# RCSS_SCI register map
Vendor: Texas Instruments
Peripheral module from a debugger description file (folder am273).
Registers are 32-bit, access per field, no defined reset value unless marked. A register's access mark holds for its fields unless they carry their own. Offsets are as the file gives them; lines under a group give offsets from that group; [hi:lo] are bit positions; {n}, {i} and the like mark numbered series; 'fields as' and 'values as' point back to an identical list; <NAME> marks a mode.

## RCSS_SCI
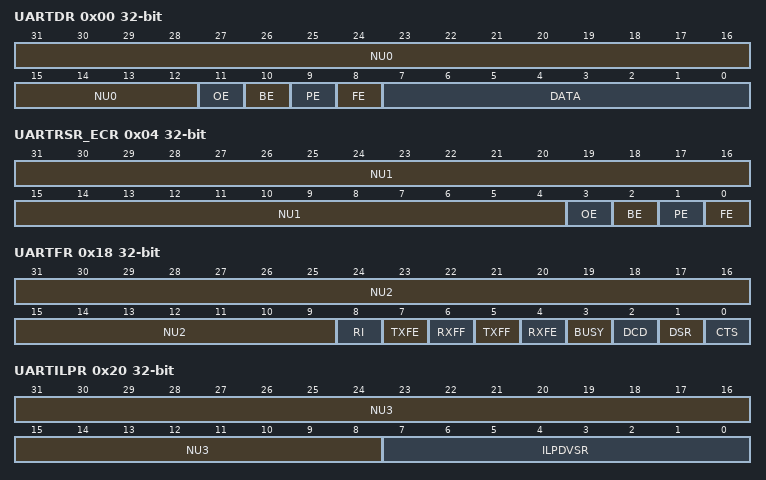
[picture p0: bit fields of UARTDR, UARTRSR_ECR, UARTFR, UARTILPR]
0x00 UARTDR — Data Register, UARTDR
  [31:12] NU0 ro — Reserved.
  [11] OE rw — Overrun error. This bit is set to 1 if data is received and the receive FIFO is already full. This is cleared to 0 once there is an empty space in the FIFO and a new character can be written to it.
  [10] BE rw — Break error. This bit is set to 1 if a break condition was detected, indicating that the received data input was held LOW for longer than a full-word transmission time (defined as start, data, parity and stop bits). In FIFO mode, this error is associated with the character at the top of the FIFO. When a break occurs, only one 0 character is loaded into the FIFO. The next character is only enabled after the receive data input goes to a 1 (marking state), and the next valid start bit is received
  [9] PE rw — Parity error. When set to 1, it indicates that the parity of the received data character does not match the parity that the EPS and SPS bits in the Line Control Register, UARTLCR. In FIFO mode, this error is associated with the character at the top of the FIFO.
  [8] FE rw — Framing error. When set to 1, it indicates that the received character did not have a valid stop bit (a valid stop bit is 1). In FIFO mode, this error is associated with the character at the top of the FIFO
  [7:0] DATA rw — Receive data character & Transmit data character
0x04 UARTRSR_ECR — Receive Status Register/Error Clear Register,
  [31:4] NU1 ro — Reserved, unpredictable when read
  [3] OE rw — Overrun error. This bit is set to 1 if data is received and the FIFO is already full. This bit is cleared to 0 by a write to UARTECR. The FIFO contents remain valid because no more data is written when the FIFO is full, only the contents of the shift register are overwritten. The CPU must now read the data, to empty the FIFO.
  [2] BE rw — Break error. This bit is set to 1 if a break condition was detected, indicating that the received data input was held LOW for longer than a full-word transmission time (defined as start, data, parity, and stop bits). This bit is cleared to 0 after a write to UARTECR. In FIFO mode, this error is associated with the character at the top of the FIFO. When a break occurs, only one 0 character is loaded into the FIFO. The next character is only enabled after the receive data input goes to a 1 (marking state) and the next valid start bit is received.
  [1] PE rw — Parity error. When set to 1, it indicates that the parity of the received data character does not match the parity that the EPS and SPS bits in the Line Control Register, UARTLCR_H. This bit is cleared to 0 by a write to UARTECR. In FIFO mode, this error is associated with the character at the top of the FIFO.
  [0] FE rw — Framing error. When set to 1, it indicates that the received character did not have a valid stop bit (a valid stop bit is 1). This bit is cleared to 0 by a write to UARTECR. In FIFO mode, this error is associated with the character at the top of the FIFO.
0x18 UARTFR ro — Flag Register, UARTFR
  [31:9] NU2 — Reserved, do not modify, read as zero.
  [8] RI — Ring indicator. This bit is the complement of the UART ring indicator, nUARTRI, modem status input. That is, the bit is 1 when nUARTRI is LOW.
  [7] TXFE — Transmit FIFO empty. The meaning of this bit depends on the state of the FEN bit in the Line Control Register, UARTLCR_H. If the FIFO is disabled, this bit is set when the transmit holding register is empty.If the FIFO is enabled, the TXFE bit is set when the transmit FIFO is empty. This bit does not indicate if there is data in the transmit shift register.
  [6] RXFF — Receive FIFO full. The meaning of this bit depends on the state of the FEN bit in the UARTLCR_H Register. If the FIFO is disabled, this bit is set when the receive holding register is full. If the FIFO is enabled, the RXFF bit is set when the receive FIFO is full.
  [5] TXFF — Transmit FIFO full. The meaning of this bit depends on the state of the FEN bit in the UARTLCR_H Register. If the FIFO is disabled, this bit is set when the transmit holding register is full. If the FIFO is enabled, the TXFF bit is set when the transmit FIFO is full.
  [4] RXFE — Receive FIFO empty. The meaning of this bit depends on the state of the FEN bit in the UARTLCR_H Register. If the FIFO is disabled, this bit is set when the receive holding register is empty. If the FIFO is enabled, the RXFE bit is set when the receive FIFO is empty.
  [3] BUSY — UART busy. If this bit is set to 1, the UART is busy transmitting data. This bit remains set until the complete byte, including all the stop bits, has been sent from the shift register. This bit is set as soon as the transmit FIFO becomes non-empty, regardless of whether the UART is enabled or not.
  [2] DCD — Data carrier detect. This bit is the complement of the UART data carrier detect, nUARTDCD, modem status input. That is, the bit is 1 when nUARTDCD is LOW.
  [1] DSR — Data set ready. This bit is the complement of the UART data set ready, nUARTDSR, modem status input. That is, the bit is 1 when nUARTDSR is LOW.
  [0] CTS — Clear to send. This bit is the complement of the
0x20 UARTILPR — IrDA Low-Power Counter Register, UARTILPR
  [31:8] NU3 ro — Reserved.
  [7:0] ILPDVSR rw — 8-bit low-power divisor value. NOTE Zero is an illegal value. Programming a zero value results in no IrLPBaud16 pulses being generated
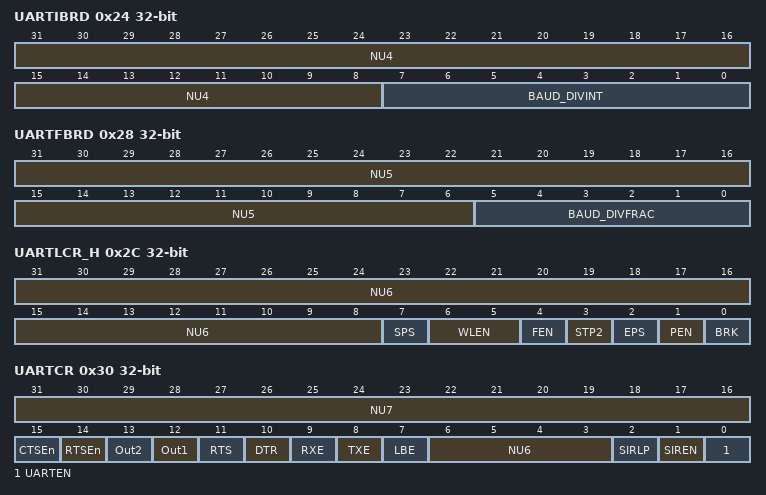
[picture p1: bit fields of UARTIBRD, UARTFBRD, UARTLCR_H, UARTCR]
0x24 UARTIBRD — Integer Baud Rate Register, UARTIBRD
  [31:8] NU4 ro — Reserved.
  [7:0] BAUD_DIVINT rw — The fractional baud rate divisor.
0x28 UARTFBRD — Fractional Baud Rate Register, UARTFBRD
  [31:6] NU5 ro — Reserved.
  [5:0] BAUD_DIVFRAC rw — The fractional baud rate divisor. Baud rate divisor BAUDDIV = (FUARTCLK/(16�Baud rate)) where FUARTCLK is the UART reference clock frequency. If the required baud rate is 230400 and UARTCLK = 4MHz then: Baud Rate Divisor = (4�106)/(16�230400) = 1.085 This means BRDI = 1 and BRDF = 0.085. Therefore, fractional part, m = integer((0.085�64)+0.5) = 5 Generated baud rate divider = 1+5/64 = 1.078 Generated baud rate = (4�106)/(16�1.078) = 231911 Error = (231911-230400)/230400 � 100 = 0.656% The maximum error using a 6-bit UARTFBRD Register = 1/64�100 = 1.56%. This occurs when m = 1, and the error is cumulative over 64 clock ticks.
0x2C UARTLCR_H — Line Control Register, UARTLCR_H
  [31:8] NU6 ro — Reserved, do not modify, read as zero.
  [7] SPS rw — Stick parity select. 0 = stick parity is disabled 1 = if the EPS bit is 0 then the parity bit is transmitted and checked as a 1 & if the EPS bit is 1 then the parity bit is transmitted and checked as a 0. This bit has no effect when the PEN bit disables parity checking and generation.
  [6:5] WLEN rw — Word length. These bits indicate the number of data bits transmitted or received in a frame as follows b11 = 8 bits b10 = 7 bits b01 = 6 bits b00 = 5 bits.
  [4] FEN rw — Enable FIFOs: 0 = FIFOs are disabled (character mode) that is, the FIFOs become 1-byte-deep holding registers 1 = transmit and receive FIFO buffers are enabled (FIFO mode).
  [3] STP2 rw — Two stop bits select. If this bit is set to 1, two stop bits are transmitted at the end of the frame. The receive logic does not check for two stop bits being received.
  [2] EPS rw — Even parity select. Controls the type of parity the UART uses during transmission and reception: 0 = odd parity. The UART generates or checks for an odd number of 1s in the data and parity bits. 1 = even parity. The UART generates or checks for an even number of 1s in the data and parity bits. This bit has no effect when the PEN bit disables parity checking and generation.
  [1] PEN rw — Parity enable: 0 = parity is disabled and no parity bit added to the data frame 1 = parity checking and generation is enabled.
  [0] BRK rw — Send break. If this bit is set to 1, a low-level is continually output on the UARTTXD output, after completing transmission of the current character. For the proper execution of the break command, the software must set this bit for at least two complete frames. For normal use, this bit must be cleared to 0.
0x30 UARTCR — Control Register, UARTCR
  [31:16] NU7 ro — Reserved, do not modify, read as zero.
  [15] CTSEn rw — CTS hardware flow control enable. If this bit is set to 1, CTS hardware flow control is enabled. Data is only transmitted when the nUARTCTS signal is asserted.
  [14] RTSEn rw — RTS hardware flow control enable. If this bit is set to 1, RTS hardware flow control is enabled. Data is only requested when there is space in the receive FIFO for it to be received.
  [13] Out2 rw — This bit is the complement of the UART Out2 (nUARTOut2) modem status output. That is, when the bit is programmed to a 1, the output is 0. For DTE this can be used as Ring Indicator (RI).
  [12] Out1 rw — This bit is the complement of the UART Out1 (nUARTOut1) modem status output. That is, when the bit is programmed to a 1 the output is 0. For DTE this can be used as Data Carrier Detect (DCD).
  [11] RTS rw — Request to send. This bit is the complement of the UART request to send, nUARTRTS, modem status output. That is, when the bit is programmed to a 1 then nUARTRTS is LOW.
  [10] DTR rw — Data transmit ready. This bit is the complement of the UART data transmit ready, nUARTDTR, modem status output. That is, when the bit is programmed to a 1 then nUARTDTR is LOW.
  [9] RXE rw — Receive enable. If this bit is set to 1, the receive section of the UART is enabled. Data reception occurs for either UART signals or SIR signals depending on the setting of the SIREN bit. When the UART is disabled in the middle of reception, it completes the current character before stopping.
  [8] TXE rw — Transmit enable. If this bit is set to 1, the transmit section of the UART is enabled. Data transmission occurs for either UART signals, or SIR signals depending on the setting of the SIREN bit. When the UART is disabled in the middle of transmission, it completes the current character before stopping.
  [7] LBE rw — Loopback enable. If this bit is set to 1 and the SIREN bit is set to 1 and the SIRTEST bit in the Test Control Register, UARTTCR on page 4-5 is set to 1, then the nSIROUT path is inverted, and fed through to the SIRIN path. The SIRTEST bit in the test register must be set to 1 to override the normal half-duplex SIR operation. This must be the requirement for accessing the test registers during normal operation, and SIRTEST must be cleared to 0 when loopback testing is finished. This feature reduces the amount of external coupling required during system test. If this bit is set to 1, and the SIRTEST bit is set to 0, the UARTTXD path is fed through to the UARTRXD path. In either SIR mode or UART mode, when this bit is set, the modem outputs are also fed through to the modem inputs. This bit is cleared to 0 on reset, to disable loopback.
  [6:3] NU6 ro — Reserved, do not modify, read as zero.
  [2] SIRLP rw — SIR low-power IrDA mode. This bit selects the IrDA encoding mode. If this bit is cleared to 0, low-level bits are transmitted as an active high pulse with a width of 3/16th of the bit period. If this bit is set to 1, low-level bits are transmitted with a pulse width that is 3 times the period of the IrLPBaud16 input signal, regardless of the selected bit rate. Setting this bit uses less power, but might reduce transmission distances.
  [1] SIREN rw — SIR enable: 0 = IrDA SIR ENDEC is disabled. nSIROUT remains LOW (no light pulse generated), and signal transitions on SIRIN have no effect. 1 = IrDA SIR ENDEC is enabled. Data is transmitted and received on nSIROUT and SIRIN. UARTTXD remains HIGH, in the marking state. Signal transitions on UARTRXD or modem status inputs have no effect. This bit has no effect if the UARTEN bit disables the UART.
  [0] UARTEN rw — UART enable: 0 = UART is disabled. If the UART is disabled in the middle of transmission or reception, it completes the current character before stopping. 1 = the UART is enabled. Data transmission and reception occurs for either UART signals or SIR signals depending on the setting of the SIREN bit.
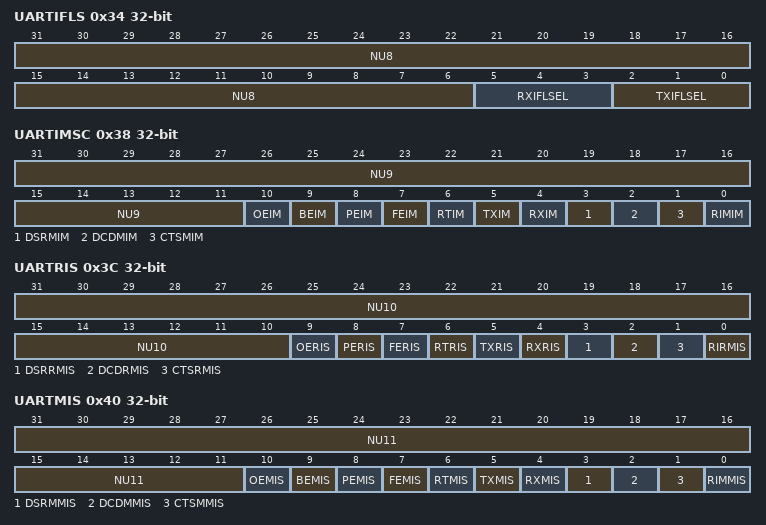
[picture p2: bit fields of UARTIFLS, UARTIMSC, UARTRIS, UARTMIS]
0x34 UARTIFLS — Interrupt FIFO Level Select Register, UARTIFLS
  [31:6] NU8 ro — Reserved, do not modify, read as zero.
  [5:3] RXIFLSEL rw — Receive interrupt FIFO level select. The trigger points for the receive interrupt are as follows: b000 = Receive FIFO becomes ≥ 1/8 full b001 = Receive FIFO becomes ≥ 1/4 full b010 = Receive FIFO becomes ≥ 1/2 full b011 = Receive FIFO becomes ≥ 3/4 full b100 = Receive FIFO becomes ≥ 7/8 full b101-b111 = reserved.
  [2:0] TXIFLSEL rw — Transmit interrupt FIFO level select. The trigger points for the transmit interrupt are as follows: b000 = Transmit FIFO becomes ≤ 1/8 full b001 = Transmit FIFO becomes ≤ 1/4 full b010 = Transmit FIFO becomes ≤ 1/2 full b011 = Transmit FIFO becomes ≤ 3/4 full b100 = Transmit FIFO becomes ≤ 7/8 full b101-b111 = reserved.
0x38 UARTIMSC — Interrupt Mask Set/Clear Register, UARTIMSC
  [31:11] NU9 ro — Reserved, read as zero, do not modify.
  [10] OEIM rw — Overrun error interrupt mask. A read returns the current mask for the UARTOEINTR interrupt.On a write of 1, the mask of the UARTOEINTR interrupt is set. A write of 0 clears the mask.
  [9] BEIM rw — Break error interrupt mask. A read returns the current mask for the UARTBEINTR interrupt. On a write of 1, the mask of the UARTBEINTR interrupt is set. A write of 0 clears the mask.
  [8] PEIM rw — Parity error interrupt mask. A read returns the current mask for the UARTPEINTR interrupt.On a write of 1, the mask of the UARTPEINTR interrupt is set. A write of 0 clears the mask.
  [7] FEIM rw — Framing error interrupt mask. A read returns the current mask for the UARTFEINTR interrupt.On a write of 1, the mask of the UARTFEINTR interrupt is set. A write of 0 clears the mask.
  [6] RTIM rw — Receive timeout interrupt mask. A read returns the current mask for the UARTRTINTR interrupt.On a write of 1, the mask of the UARTRTINTR interrupt is set. A write of 0 clears the mask.
  [5] TXIM rw — Transmit interrupt mask. A read returns the current mask for the UARTTXINTR interrupt.On a write of 1, the mask of the UARTTXINTR interrupt is set. A write of 0 clears the mask.
  [4] RXIM rw — Receive interrupt mask. A read returns the current mask for the UARTRXINTR interrupt.On a write of 1, the mask of the UARTRXINTR interrupt is set. A write of 0 clears the mask.
  [3] DSRMIM rw — nUARTDSR modem interrupt mask. A read returns the current mask for the UARTDSRINTR interrupt.On a write of 1, the mask of the UARTDSRINTR interrupt is set. A write of 0 clears the mask.
  [2] DCDMIM rw — nUARTDCD modem interrupt mask. A read returns the current mask for the UARTDCDINTR interrupt.On a write of 1, the mask of the UARTDCDINTR interrupt is set. A write of 0 clears the mask.
  [1] CTSMIM rw — nUARTCTS modem interrupt mask. A read returns the current mask for the UARTCTSINTR interrupt. On a write of 1, the mask of the UARTCTSINTR interrupt is set. A write of 0 clears the mask.
  [0] RIMIM rw — nUARTRI modem interrupt mask. A read returns the current mask for the UARTRIINTR interrupt.On a write of 1, the mask of the UARTRIINTR interrupt is set. A write of 0 clears the mask.
0x3C UARTRIS ro — Raw Interrupt Status Register, UARTRIS
  [31:10] NU10 — Reserved, read as zero, do not modify.
  [9] OERIS — Overrun error interrupt status. Returns the raw interrupt state of the UARTOEINTR interrupt. BERIS Break error interrupt status. Returns the raw interrupt state of the UARTBEINTR interrupt.
  [8] PERIS — Parity error interrupt status. Returns the raw interrupt state of the UARTPEINTR interrupt.
  [7] FERIS — Framing error interrupt status. Returns the raw interrupt state of the UARTFEINTR interrupt.
  [6] RTRIS — Receive timeout interrupt status. Returns the raw interrupt state of the UARTRTINTR interrupt.
  [5] TXRIS — Transmit interrupt status. Returns the raw interrupt state of the UARTTXINTR interrupt.
  [4] RXRIS — Receive interrupt status. Returns the raw interrupt state of the UARTRXINTR interrupt.
  [3] DSRRMIS — nUARTDSR modem interrupt status. Returns the raw interrupt state of the UARTDSRINTR interrupt.
  [2] DCDRMIS — nUARTDCD modem interrupt status. Returns the raw interrupt state of the UARTDCDINTR interrupt.
  [1] CTSRMIS — nUARTCTS modem interrupt status. Returns the raw interrupt state of the UARTCTSINTR interrupt.
  [0] RIRMIS — nUARTRI modem interrupt status. Returns the raw interrupt state of the UARTRIINTR interrupt.
0x40 UARTMIS ro — Masked Interrupt Status Register, UARTMIS
  [31:11] NU11 — Reserved, read as zero, do not modify
  [10] OEMIS — Overrun error masked interrupt status. Returns the masked interrupt state of the UARTOEINTR interrupt.
  [9] BEMIS — Break error masked interrupt status. Returns the masked interrupt state of the UARTBEINTR interrupt.
  [8] PEMIS — Parity error masked interrupt status. Returns the masked interrupt state of the UARTPEINTR interrupt.
  [7] FEMIS — Framing error masked interrupt status. Returns the masked interrupt state of the UARTFEINTR interrupt.
  [6] RTMIS — Receive timeout masked interrupt status. Returns the masked interrupt state of the UARTRTINTR interrupt.
  [5] TXMIS — Transmit masked interrupt status. Returns the masked interrupt state of the UARTTXINTR interrupt.
  [4] RXMIS — Receive masked interrupt status. Returns the masked interrupt state of the UARTRXINTR interrupt.
  [3] DSRMMIS — nUARTDSR modem masked interrupt status. Returns the masked interrupt state of the UARTDSRINTR interrupt.
  [2] DCDMMIS — nUARTDCD modem masked interrupt status. Returns the masked interrupt state of the UARTDCDINTR interrupt.
  [1] CTSMMIS — nUARTCTS modem masked interrupt status. Returns the masked interrupt state of the UARTCTSINTR interrupt.
  [0] RIMMIS — nUARTRI modem masked
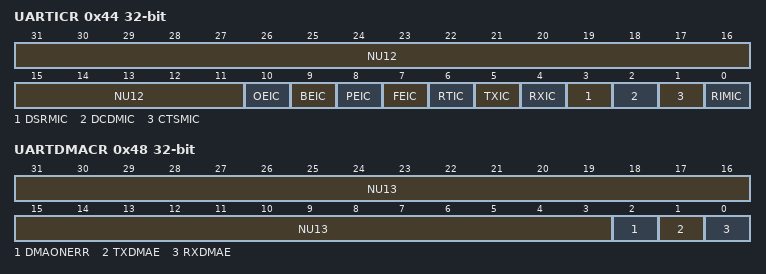
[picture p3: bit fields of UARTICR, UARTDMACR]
0x44 UARTICR — Interrupt Clear Register, UARTICR
  [31:11] NU12 ro — Reserved, read as zero, do not modify.
  [10] OEIC wo — Overrun error interrupt clear. Clears the UARTOEINTR interrupt.
  [9] BEIC wo — Break error interrupt clear. Clears the UARTBEINTR interrupt.
  [8] PEIC wo — Parity error interrupt clear. Clears the UARTPEINTR interrupt.
  [7] FEIC wo — Framing error interrupt clear. Clears the UARTFEINTR interrupt.
  [6] RTIC wo — Receive timeout interrupt clear. Clears the UARTRTINTR interrupt.
  [5] TXIC wo — Transmit interrupt clear. Clears the UARTTXINTR interrupt.
  [4] RXIC wo — Receive interrupt clear. Clears the UARTRXINTR interrupt.
  [3] DSRMIC wo — nUARTDSR modem interrupt clear. Clears the UARTDSRINTR interrupt.
  [2] DCDMIC wo — nUARTDCD modem interrupt clear. Clears the UARTDCDINTR interrupt.
  [1] CTSMIC wo — nUARTCTS modem interrupt clear. Clears the UARTCTSINTR interrupt.
  [0] RIMIC wo — nUARTRI modem interrupt clear. Clears the UARTRIINTR interrupt.
0x48 UARTDMACR — DMA Control Register, UARTDMACR
  [31:3] NU13 ro — Reserved, read as zero, do not modify.
  [2] DMAONERR rw — DMA on error. If this bit is set to 1, the DMA receive request outputs, UARTRXDMASREQ or UARTRXDMABREQ, are disabled when the UART error interrupt is asserted.
  [1] TXDMAE rw — Transmit DMA enable. If this bit is set to 1, DMA for the transmit FIFO is enabled.
  [0] RXDMAE rw — Receive DMA enable. If this bit is set to 1, DMA for the receive FIFO is enabled.
{0xFE0+4i} UARTPeriphID{i} ro (i=0..3) — Peripheral Identification Registers UARTPeriphID{i}
{0xFF0+4i} UARTPCellID{i} ro (i=0..3) — PrimeCell Identification Registers UARTPCellID{i}
